# MCXA156 register map
Vendor: nxp.com; File version: 1.0
CPU: CM33 r2p0, little endian, no MPU, FPU, VTOR, 3 interrupt priority bits
Registers are 32-bit, read-write, reset 0x0 unless marked. A register's access mark holds for its fields unless they carry their own. Offsets are from the block's base; [hi:lo] are bit positions; lines under a group give offsets from that group; {n}, {i} and the like mark numbered series; 'fields as' and 'values as' point back to an identical list.

## I3C0 — I3C
Base 0x40002000
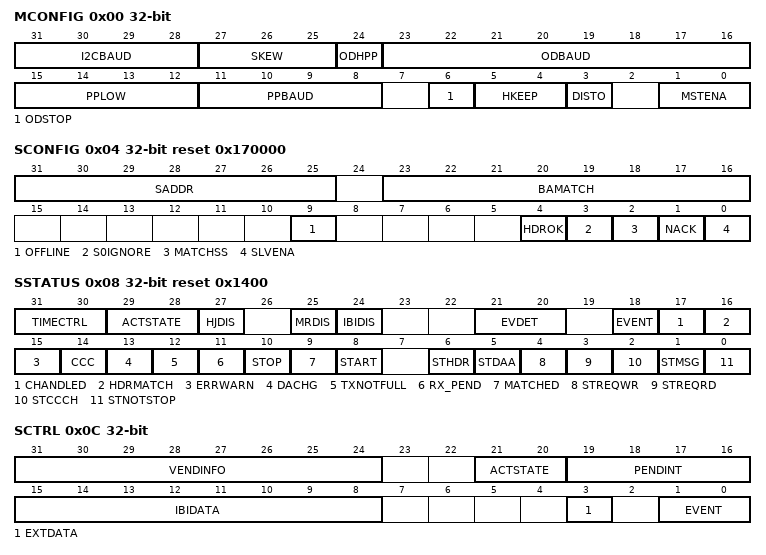
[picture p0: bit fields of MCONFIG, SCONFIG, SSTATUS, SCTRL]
0x00 MCONFIG — Controller Configuration
  [31:28] I2CBAUD — I2C Baud Rate
  [27:25] SKEW
  [24] ODHPP — Open Drain High Push-Pull
    0=DISABLE; 1=ENABLE
  [23:16] ODBAUD — Open Drain Baud Rate
  [15:12] PPLOW — Push-Pull Low
  [11:8] PPBAUD — Push-Pull Baud Rate
  [6] ODSTOP — Open Drain Stop
    0=DISABLE; 1=ENABLE
  [5:4] HKEEP — High-Keeper
    0=NONE; 1=WIRED_IN; 2=PASSIVE_SDA; 3=PASSIVE_ON_SDA_SCL
  [3] DISTO — Disable Timeout
    0=ENABLE (Enabled); 1=DISABLE (Disabled, if configured)
  [1:0] MSTENA — Controller Enable
    0=MASTER_OFF (CONTROLLER_OFF); 1=MASTER_ON (CONTROLLER_ON); 2=MASTER_CAPABLE (CONTROLLER_CAPABLE); 3=I2C_MASTER_MODE (I2C_CONTROLLER_MODE)
0x04 SCONFIG reset 0x170000 — Target Configuration
  [31:25] SADDR — Static Address
  [23:16] BAMATCH — Bus Available Match
  [9] OFFLINE
    0=DISABLE; 1=ENABLE
  [4] HDROK
    0=DISABLE (Disable HDR OK); 1=ENABLE (Enable HDR OK)
  [3] S0IGNORE — Ignore TE0 or TE1 Errors
    0=DISABLE (Do not ignore TE0 or TE1 errors); 1=ENABLE (Ignore TE0 or TE1 errors)
  [2] MATCHSS — Match Start or Stop
    0=DISABLE; 1=ENABLE
  [1] NACK — Not Acknowledge
    0=DISABLE (Always disable NACK mode); 1=ENABLE (Always enable NACK mode (works normally))
  [0] SLVENA — Target Enable
    0=DISABLE; 1=ENABLE
0x08 SSTATUS reset 0x1400 — Target Status
  [31:30] TIMECTRL ro — Time Control
    0=NO_TIME_CONTROL (NO_TIME_CONTROL (no time control is enabled)); 1=SYNC (SYNC_MODE (Synchronous mode is enabled)); 2=ASYNC_MODE (ASYNC_MODE (Asynchronous standard mode (0 or 1) is enabled)); 3=BOTHSYNCASYNC (BOTHSYNCASYNC (both Synchronous and Asynchronous modes are enabled))
  [29:28] ACTSTATE ro — Activity State from Common Command Codes (CCC)
    0=NO_LATENCY (NO_LATENCY (normal bus operations)); 1=LATENCY_1MS (LATENCY_1MS (1 ms of latency)); 2=LATENCY_100MS (LATENCY_100MS (100 ms of latency)); 3=LATENCY_10S (LATENCY_10S (10 seconds of latency))
  [27] HJDIS ro — Hot-Join Disabled
    0=MR_ENABLED (Enabled); 1=MR_DISABLED (Disabled)
  [25] MRDIS ro — Controller Requests Disable
    0=MR_ENABLED (Enabled); 1=MR_DISABLED (Disabled)
  [24] IBIDIS ro — In-Band Interrupts Disable
    0=INTERRUPTS_ENABLED (Enabled); 1=INTERRUPTS_DISABLED (Disabled)
  [21:20] EVDET ro — Event Details
    0=NONE (NONE (no event or no pending event)); 1=NO_REQUEST (NO_REQUEST (request is not sent yet; either there is no START condition yet, or is waiting for Bus-Available or Bus-Idle (HJ))); 2=NACKED (NACKed (not acknowledged, request sent and rejected); I3C tries again); 3=ACKED (ACKed (acknowledged; request sent and accepted), so done (unless the time control data is still being sent))
  [18] EVENT write-1-clears
    on read: 0=NO_EVENT (No event occurred); 1=EVENT (IBI, CR, or HJ occurred)
  [17] CHANDLED write-1-clears — Common Command Code Handled
    on read: 0=NOT_HANDLED (CCC handling not in progress); 1=HANDLED (CCC handling in progress)
  [16] HDRMATCH write-1-clears — High Data Rate Command Match
    on read: 0=NO_MATCH (Did not match); 1=MATCH (Matched the I3C dynamic address)
  [15] ERRWARN ro — Error Warning
  [14] CCC write-1-clears — Common Command Code
    on read: 0=NO_CCC_RECEIVED (CCC not received); 1=CCC_RECEIVED
  [13] DACHG write-1-clears — Dynamic Address Change
    on read: 0=NO_CHANGE_DETECTED (No DA change detected); 1=CHANGE_DETECTED (DA change detected)
  [12] TXNOTFULL ro — Transmit Buffer Not Full
    0=FULL (Transmit buffer full); 1=NOT_FULL (Transmit buffer not full)
  [11] RX_PEND ro — Received Message Pending
    0=NO_MSG_PENDING (No received message pending); 1=MSG_PENDING (Received message pending)
  [10] STOP write-1-clears
    on read: 0=NO_STOP_DETECTED (No Stopped state detected); 1=STOP_DETECTED (Stopped state detected)
  [9] MATCHED write-1-clears
    on read: 0=NOT_MATCHED (Header not matched); 1=MATCHED (Header matched)
  [8] START write-1-clears
    on read: 0=START_NOT_DETECTED (Not detected); 1=START_DETECTED (Detected)
  [6] STHDR ro — Status High Data Rate
    0=NOT_IN_HDR_DDR (I3C bus not in HDR-DDR mode); 1=IN_HDR_DDR (I3C bus in HDR-DDR mode)
  [5] STDAA ro — Status Dynamic Address Assignment
    0=NOT_IN_ENTDAA (Not in ENTDAA mode); 1=IN_ENTDAA (In ENTDAA mode)
  [4] STREQWR ro — Status Request Write
    0=IDLE (Not an SDR write); 1=BUSY (SDR write data from the controller, but not in ENTDAA mode)
  [3] STREQRD ro — Status Request Read
    0=IDLE (Not an SDR read); 1=BUSY (SDR read from this target or an IBI is being pushed out)
  [2] STCCCH ro — Status Common Command Code Handler
    0=IDLE (No CCC message handled); 1=BUSY (Handled automatically)
  [1] STMSG ro — Status Message
    0=IDLE; 1=BUSY
  [0] STNOTSTOP ro — Status not Stop
    0=STOPPED (In STOP condition); 1=BUSY
0x0C SCTRL — Target Control
  [31:24] VENDINFO — Vendor Information
  [21:20] ACTSTATE — Activity State of Target
  [19:16] PENDINT — Pending Interrupt
  [15:8] IBIDATA — In-Band Interrupt Data
  [3] EXTDATA — Extended Data
    0=DISABLE; 1=ENABLE
  [1:0] EVENT
    0=NORMAL_MODE; 1=IBI; 2=MASTER_REQUEST (CONTROLLER_REQUEST); 3=HOT_JOIN_REQUEST
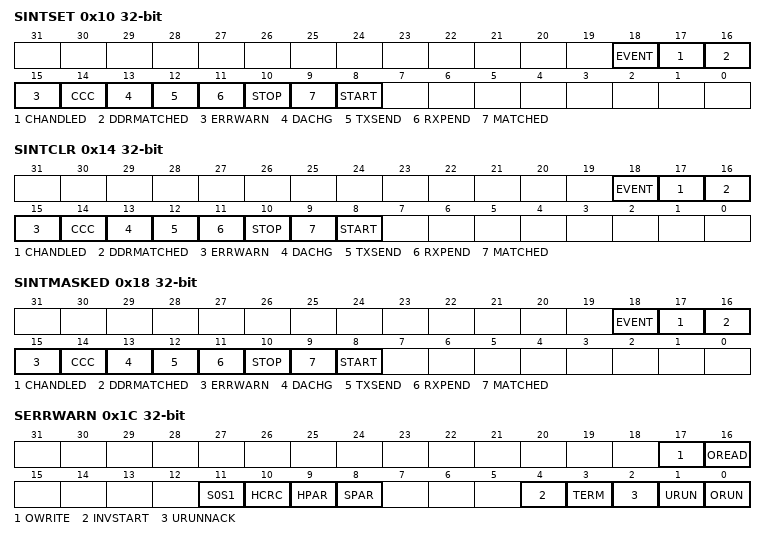
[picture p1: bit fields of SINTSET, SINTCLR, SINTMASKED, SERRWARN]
0x10 SINTSET write-1-sets — Target Interrupt Set
  [all] fields
    0=DISABLE; 1=ENABLE
  [18] EVENT write-1-sets — Event Interrupt Enable
  [17] CHANDLED write-1-sets — Common Command Code (CCC) Interrupt Enable
  [16] DDRMATCHED write-1-sets — Double Data Rate Interrupt Enable
  [15] ERRWARN write-1-sets — Error or Warning Interrupt Enable
  [14] CCC write-1-sets — Common Command Code (CCC) Interrupt Enable
  [13] DACHG write-1-sets — Dynamic Address Change Interrupt Enable
  [12] TXSEND write-1-sets — Transmit Interrupt Enable
  [11] RXPEND write-1-sets — Receive Interrupt Enable
  [10] STOP write-1-sets — Stop Interrupt Enable
  [9] MATCHED write-1-sets — Match Interrupt Enable
  [8] START write-1-sets — Start Interrupt Enable
0x14 SINTCLR reset not defined write-1-clears — Target Interrupt Clear
  [18] EVENT write-1-clears — EVENT Interrupt Enable Clear
  [17] CHANDLED write-1-clears — CHANDLED Interrupt Enable Clear
  [16] DDRMATCHED write-1-clears — DDRMATCHED Interrupt Enable Clear
  [15] ERRWARN write-1-clears — ERRWARN Interrupt Enable Clear
  [14] CCC write-1-clears — CCC Interrupt Enable Clear
  [13] DACHG write-1-clears — DACHG Interrupt Enable Clear
  [12] TXSEND write-1-clears — TXSEND Interrupt Enable Clear
  [11] RXPEND write-1-clears — RXPEND Interrupt Enable Clear
  [10] STOP write-1-clears — STOP Interrupt Enable Clear
  [9] MATCHED write-1-clears — Matched Interrupt Enable Clear
  [8] START write-1-clears — START Interrupt Enable Clear
0x18 SINTMASKED ro — Target Interrupt Mask
  [18] EVENT — EVENT Interrupt Mask
  [17] CHANDLED — CHANDLED Interrupt Mask
  [16] DDRMATCHED — DDRMATCHED Interrupt Mask
  [15] ERRWARN — ERRWARN Interrupt Mask
  [14] CCC — CCC Interrupt Mask
  [13] DACHG — DACHG Interrupt Mask
  [12] TXSEND — TXSEND Interrupt Mask
  [11] RXPEND — RXPEND Interrupt Mask
  [10] STOP — STOP Interrupt Mask
  [9] MATCHED — MATCHED Interrupt Mask
  [8] START — START Interrupt Mask
0x1C SERRWARN write-1-clears — Target Errors and Warnings
  [17] OWRITE write-1-clears — Over-Write Error
    on read: 0=NO_ERROR (No overwrite error); 1=ERROR (Overwrite error)
  [16] OREAD write-1-clears — Over-Read Error
    on read: 0=NO_ERROR (No over-read error); 1=ERROR (Over-read error)
  [11] S0S1 write-1-clears — TE0 or TE1 Error
    on read: 0=NO_ERROR (No TE0 or TE1 error occurred); 1=ERROR (TE0 or TE1 error occurred)
  [10] HCRC write-1-clears — HDR-DDR CRC Error
    on read: 0=NO_ERROR (No HDR-DDR CRC error occurred); 1=ERROR (HDR-DDR CRC error occurred)
  [9] HPAR write-1-clears — HDR Parity Error
    on read: 0=NO_ERROR (No HDR parity error); 1=ERROR (HDR parity error)
  [8] SPAR write-1-clears — SDR Parity Error
    on read: 0=NO_ERROR (No SDR parity error); 1=ERROR (SDR parity error)
  [4] INVSTART write-1-clears — Invalid Start Error
    on read: 0=NO_ERROR (No invalid start error); 1=ERROR (Invalid start error)
  [3] TERM write-1-clears — Terminated Error
    on read: 0=NO_ERROR (No terminated error); 1=ERROR (Terminated error)
  [2] URUNNACK write-1-clears — Underrun and Not Acknowledged (NACKed) Error
    on read: 0=NO_ERROR (No underrun; not acknowledged error); 1=ERROR (Underrun; not acknowledged error)
  [1] URUN write-1-clears — Underrun Error
    on read: 0=NO_ERROR (No underrun error); 1=ERROR (Underrun error)
  [0] ORUN write-1-clears — Overrun Error
    on read: 0=NO_ERROR (No overrun error); 1=ERROR (Overrun error)
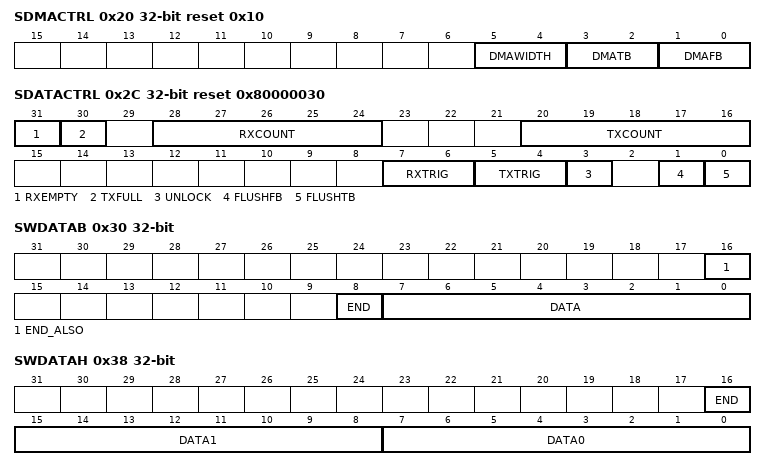
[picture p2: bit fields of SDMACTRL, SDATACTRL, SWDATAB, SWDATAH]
0x20 SDMACTRL reset 0x10 — Target DMA Control
  [5:4] DMAWIDTH — Width of DMA Operations
    0=BYTE_0; 1=BYTE_1; 2=HALF_WORD (Halfword (16 bits) (this value ensures that two bytes are available in the FIFO))
  [3:2] DMATB — DMA Write (To-Bus) Trigger
    0=NOT_USED (DMA not used); 1=ENABLE_ONE_FRAME (DMA enabled for one frame); 2=ENABLE (DMA enabled until turned off)
  [1:0] DMAFB — DMA Read (From-Bus) Trigger
    values as DMATB
0x2C SDATACTRL reset 0x80000030 — Target Data Control
  [31] RXEMPTY ro — Receive is Empty
    0=RXISNOTEMPTY (Not empty); 1=RXISEMPTY (Empty)
  [30] TXFULL ro — Transmit is Full
    0=TXISNOTFULL (Not full); 1=TXISFULL (Full)
  [28:24] RXCOUNT ro — Count of Bytes in Receive
  [20:16] TXCOUNT ro — Count of Bytes in Transmit
  [7:6] RXTRIG — Receive Trigger Level
    0=TRIGGRNOTEMPTY (Trigger when not empty); 1=TRIGGRONEFOURTH (Trigger when 1/4 or more full); 2=TRIGGRONEHALF (Trigger when 1/2 or more full); 3=TRIGGRTHREEFOURTHS (Trigger when 3/4 or more full)
  [5:4] TXTRIG — Transmit Trigger Level
    0=TRIGGREMPTY (Trigger when empty); 1=TRIGGRONEFOURTH (Trigger when 1/4 full or less); 2=TRIGGRONEHALF (Trigger when 1/2 full or less); 3=TRIGGRONELESS (Default (trigger when 1 less than full or less))
  [3] UNLOCK wo
    0=DISABLED (Cannot be changed); 1=ENABLED (Can be changed)
  [1] FLUSHFB wo — Flush From-Bus Buffer or FIFO
  [0] FLUSHTB wo — Flush To-Bus Buffer or FIFO
0x30 SWDATAB wo reset not defined — Target Write Data Byte
  [16] END_ALSO
    0=NOT_END (Not the end); 1=END
  [8] END
    0=NOT_END (Not the end); 1=END
  [7:0] DATA
0x34 SWDATABE wo reset not defined — Target Write Data Byte End
  [7:0] DATA
0x38 SWDATAH wo reset not defined — Target Write Data Halfword
  [16] END — End of Message
    0=NOT_END (Not the end); 1=END
  [15:8] DATA1
  [7:0] DATA0
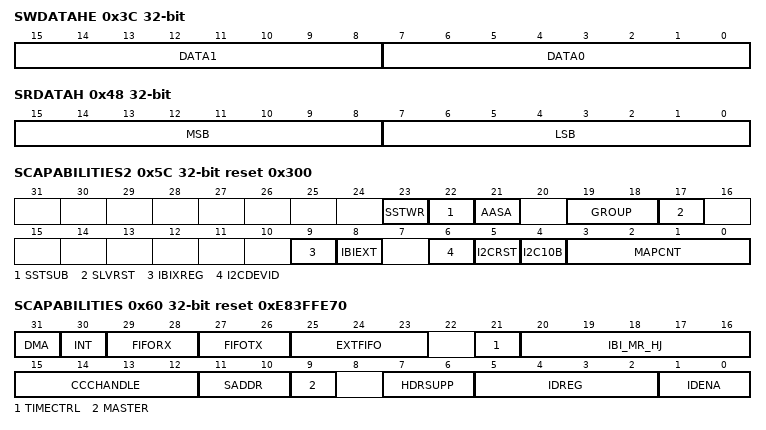
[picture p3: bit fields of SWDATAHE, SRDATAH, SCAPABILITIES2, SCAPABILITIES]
0x3C SWDATAHE wo reset not defined — Target Write Data Halfword End
  [15:8] DATA1, [7:0] DATA0
0x40 SRDATAB ro — Target Read Data Byte
  [7:0] DATA0
0x48 SRDATAH ro — Target Read Data Halfword
  [15:8] MSB — High Byte
  [7:0] LSB — Low Byte
0x54 SWDATAB1 wo (SWDATA_B_H view) — Target Write Data Byte
  [7:0] DATA
0x54 SWDATAH1 wo (SWDATA_B_H view) — Target Write Data Halfword
  [15:0] DATA
0x5C SCAPABILITIES2 ro reset 0x300 — Target Capabilities 2
  [23] SSTWR — Target-Target(s)-Tunnel Write Capable
    0=NOTSUPPORTED (Not write capable); 1=SUPPORTED (Write capable)
  [22] SSTSUB — Target-Target(s)-Tunnel Subscriber Capable
    0=NOTSUPPORTED (Not subscriber capable); 1=SUPPORTED (Subscriber capable)
  [21] AASA — SETAASA
    0=NOTSUPPORTED (SETAASA not supported); 1=SUPPORTED (SETAASA supported)
  [19:18] GROUP
    0=NOTSUPPORTED (v1.1 group addressing not supported); 1=ONE (One group supported); 2=TWO (Two groups supported); 3=THREE (Three groups supported)
  [17] SLVRST — Target Reset
    0=DISABLE (Not supported); 1=ENABLE (Supported)
  [9] IBIXREG — In-Band Interrupt Extended Register
    0=DISABLE (Not supported); 1=ENABLE (Supported)
  [8] IBIEXT — In-Band Interrupt EXTDATA
    0=DISABLE (Not supported); 1=ENABLE (Supported)
  [6] I2CDEVID — I2C Device ID
    0=DISABLE (Not supported); 1=ENABLE (Supported)
  [5] I2CRST — I2C Software Reset
    0=DISABLE (Not supported); 1=ENABLE (Supported)
  [4] I2C10B — I2C 10-bit Address
    0=DISABLE (Not supported); 1=ENABLE (Supported)
  [3:0] MAPCNT — Map Count
0x60 SCAPABILITIES ro reset 0xE83FFE70 — Target Capabilities
  [31] DMA — Direct Memory Access
    0=DMANO (Not supported); 1=DMAYES (Supported)
  [30] INT — Interrupts
    0=INTERRUPTSNO (Not supported); 1=INTERRUPTSYES (Supported)
  [29:28] FIFORX — FIFO Receive
    0=FIFO_2BYTE (Two or three); 1=FIFO_4BYTE (Four); 2=FIFO_8BYTE (Eight); 3=FIFO_16BYTE (16 or larger)
  [27:26] FIFOTX — FIFO Transmit
    0=FIFO_2BYTE (Two); 1=FIFO_4BYTE (Four); 2=FIFO_8BYTE (Eight); 3=FIFO_16BYTE (16 or larger)
  [25:23] EXTFIFO — External FIFO
    0=NO_EXT_FIFO (No external FIFO available); 1=STD_EXT_FIFO (Standard available or free external FIFO); 2=REQUEST_EXT_FIFO (Request track external FIFO)
  [21] TIMECTRL — Time Control
    0=NO_TIME_CONTROL_TYPE (No time control supported); 1=ATLEAST1_TIME_CONTROL (At least one time-control type supported)
  [20:16] IBI_MR_HJ — In-Band Interrupts, Controller Requests, Hot-Join Events
    0=ALL_DISABLED (Application cannot generate IBI, CR, or HJ); 0bxxxx1=IBI (Application can generate an IBI)
  [15:12] CCCHANDLE — Common Command Codes Handling
    0=ALL_DISABLED (All handling features disabled); 0bxxx1=BLOCK_HANDLE (The I3C module manages events, activities, status, HDR, and if enabled for it, ID and static-address-related items)
  [11:10] SADDR — Static Address
    0=NO_STATIC (No static address); 1=STATIC (Static address is fixed in hardware); 2=HW_CONTROL (Hardware controls the static address dynamically (for example, from the pin strap)); 3=CONFIG (SCONFIG register supplies the static address)
  [9] MASTER — Controller
    0=MASTERNOTSUPPORTED (Not supported); 1=MASTERSUPPORTED (Supported)
  [7:6] HDRSUPP — High Data Rate Support
    0=NO_HDR (No HDR modes supported); 1=DDR (DDR mode supported)
  [5:2] IDREG — ID Register
    0=ALL_DISABLED (All ID register features disabled); 0bxxx1=ID_INSTANCE (ID Instance is a register; used if there is no PARTNO register)
  [1:0] IDENA — ID 48b Handler
    0=APPLICATION; 1=HW (Hardware); 2=HW_BUT (Hardware, but the I3C module instance handles ID 48b); 3=PARTNO (A part number register (PARTNO))
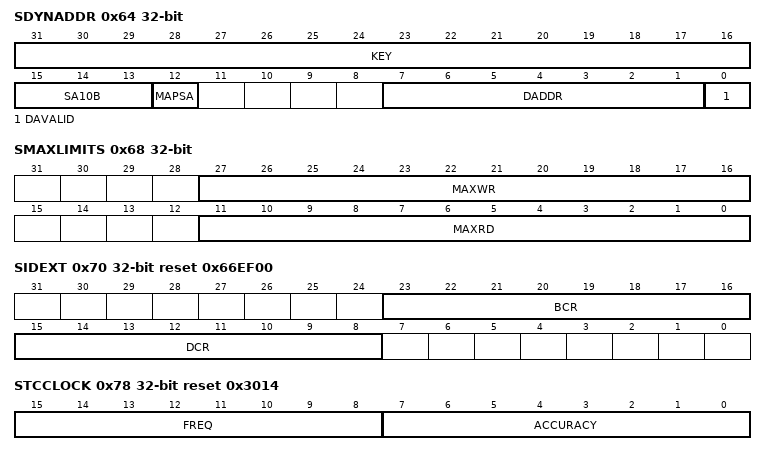
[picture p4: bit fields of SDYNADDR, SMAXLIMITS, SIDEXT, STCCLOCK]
0x64 SDYNADDR — Target Dynamic Address
  [31:16] KEY
  [15:13] SA10B wo — 10-Bit Static Address
  [12] MAPSA wo — Map a Static Address
  [7:1] DADDR — Dynamic Address
  [0] DAVALID — Dynamic Address Valid
    0=DANOTASSIGNED (DANOTASSIGNED: a dynamic address is not assigned); 1=DAASSIGNED (DAASSIGNED: a dynamic address is assigned)
0x68 SMAXLIMITS — Target Maximum Limits
  [27:16] MAXWR — Maximum Write Length
  [11:0] MAXRD — Maximum Read Length
0x6C SIDPARTNO reset 0x30000000 — Target ID Part Number
  [31:0] PARTNO — Part Number
0x70 SIDEXT reset 0x66EF00 — Target ID Extension
  [23:16] BCR — Bus Characteristics Register
  [15:8] DCR — Device Characteristic Register
0x74 SVENDORID reset 0x11B — Target Vendor ID
  [14:0] VID — Vendor ID
0x78 STCCLOCK reset 0x3014 — Target Time Control Clock
  [15:8] FREQ — Clock Frequency
  [7:0] ACCURACY — Clock Accuracy
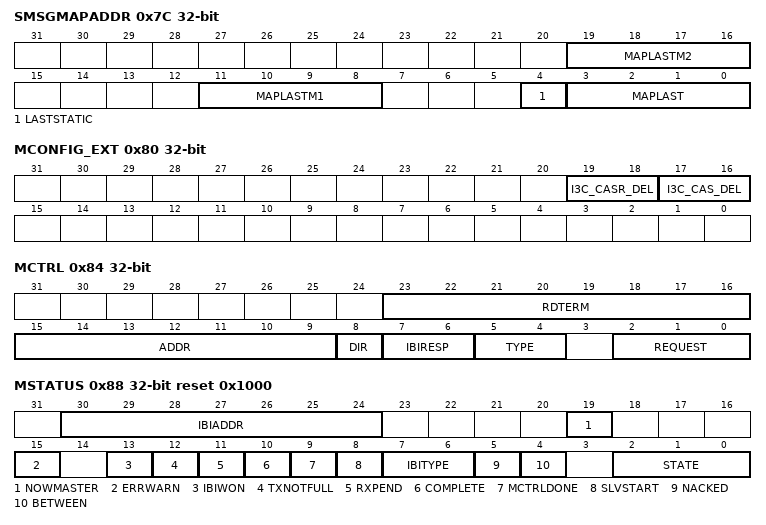
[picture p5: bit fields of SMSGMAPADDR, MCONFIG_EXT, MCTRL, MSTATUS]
0x7C SMSGMAPADDR ro — Target Message Map Address
  [19:16] MAPLASTM2 — Matched Previous Index 2
  [11:8] MAPLASTM1 — Matched Previous Address Index 1
  [4] LASTSTATIC — Last Static Address Matched
    0=I3C (I3C dynamic address); 1=I2C (I2C static address)
  [3:0] MAPLAST — Matched Address Index
0x80 MCONFIG_EXT — Controller Extended Configuration
  [19:18] I3C_CASR_DEL — I3C CAS Delay After Repeated START
    0=NO_DELAY; 1=ONE_HALF_CLK (Increases SCL clock period by 1/2); 2=ONE_CLK (Increases SCL clock period by 1); 3=ONE_AND_ONE_HALF_CLK (Increases SCL clock period by 1 1/2)
  [17:16] I3C_CAS_DEL — I3C CAS Delay After START
    0=NO_DELAY; 1=ONE_HALF_CLK (Increases SCL clock period by 1/2); 2=ONE_CLK (Increases SCL clock period by 1); 3=ONE_AND_ONE_HALF_CLK (Increases SCL clock period by 3/2)
0x84 MCTRL — Controller Control
  [23:16] RDTERM — Read Terminate Counter
  [15:9] ADDR — Address
  [8] DIR — Direction
    0=DIRWRITE (Write); 1=DIRREAD (Read)
  [7:6] IBIRESP — In-Band Interrupt Response
    0=ACK (ACK (acknowledge)); 1=NACK (NACK (reject)); 2=ACK_WITH_MANDATORY (Acknowledge with mandatory byte); 3=MANUAL
  [5:4] TYPE — Bus Type with EmitStartAddr
    0=I3C; 1=I2C; 2=DDR
  [2:0] REQUEST
    0=NONE; 1=EMITSTARTADDR; 2=EMITSTOP; 3=IBIACKNACK; 4=PROCESSDAA; 6=FORCEEXIT (Force Exit and Target Reset); 7=AUTOIBI
0x88 MSTATUS reset 0x1000 — Controller Status
  [30:24] IBIADDR ro — IBI Address
  [19] NOWMASTER write-1-clears — Module is now Controller
    on read: 0=NOT_MASTER (Not a controller); 1=MASTER (Controller)
  [15] ERRWARN ro — Error or Warning
    0=NO_ERROR (No error or warning); 1=ERROR (Error or warning)
  [13] IBIWON write-1-clears — In-Band Interrupt (IBI) Won
    on read: 0=NOT_WON (No IBI arbitration won); 1=WON (IBI arbitration won)
  [12] TXNOTFULL ro — TX Buffer or FIFO Not Full
    0=FULL (Receive buffer or FIFO full); 1=NOTFULL (Receive buffer or FIFO not full)
  [11] RXPEND ro
    0=IDLE (No receive message pending); 1=PENDING (Receive message pending)
  [10] COMPLETE write-1-clears
    on read: 0=NOT_COMPLETE; 1=COMPLETE
  [9] MCTRLDONE write-1-clears — Controller Control Done
    on read: 0=NOT_DONE; 1=DONE
  [8] SLVSTART write-1-clears — Target Start
    on read: 0=NOT_START (Target not requesting START); 1=START (Target requesting START)
  [7:6] IBITYPE ro — In-Band Interrupt (IBI) Type
    0=NONE (NONE (no IBI: this status occurs when MSTATUS[IBIWON] becomes 0)); 1=IBI; 2=MR (CR); 3=HJ
  [5] NACKED ro — Not Acknowledged
    0=NOT_NACKED; 1=NACKED (NACKed (not acknowledged))
  [4] BETWEEN ro
    0=INACTIVE (Inactive (for other cases)); 1=ACTIVE
  [2:0] STATE ro — State of the Controller
    0=IDLE (IDLE (bus has stopped)); 1=SLVREQ (SLVREQ (target request)); 2=MSGSDR; 3=NORMACT; 4=DDR (MSGDDR); 5=DAA; 6=IBIACK; 7=IBIRCV
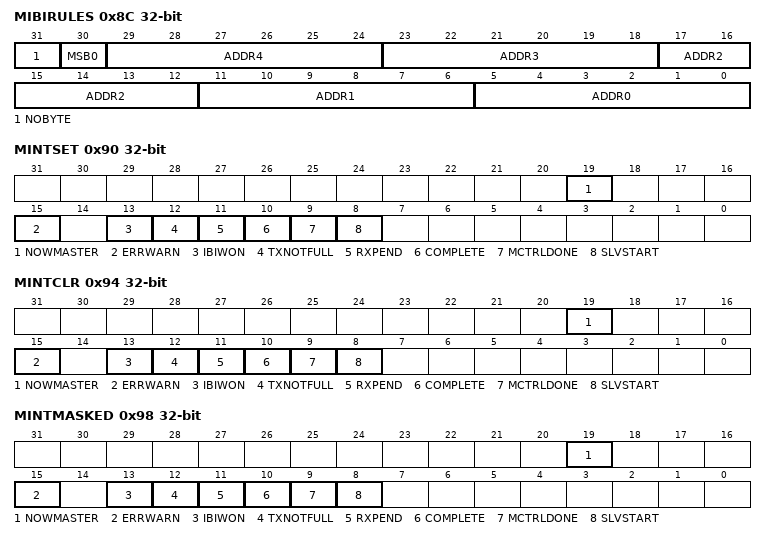
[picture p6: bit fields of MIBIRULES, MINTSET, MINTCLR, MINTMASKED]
0x8C MIBIRULES — Controller In-band Interrupt Registry and Rules
  [31] NOBYTE — No IBI byte
    0=IBIBYTE (With mandatory IBI byte); 1=NO_IBIBYTE (Without mandatory IBI byte)
  [30] MSB0 — Most Significant Address Bit is 0
    0=DISABLE (MSB is not 0); 1=ENABLE (MSB is 0)
  [6n+5:6n] ADDR{n} (n=0..4)
0x90 MINTSET write-1-sets — Controller Interrupt Set
  [19] NOWMASTER write-1-sets — Now Controller Interrupt Enable
    0=DISABLE; 1=ENABLE
  [15] ERRWARN write-1-sets — Error or Warning (ERRWARN) Interrupt Enable
    0=DISABLE; 1=ENABLE
  [13] IBIWON write-1-sets — IBI Won Interrupt Enable
    0=DISABLE; 1=ENABLE
  [12] TXNOTFULL write-1-sets — Transmit Buffer/FIFO Not Full Interrupt Enable
    0=DISABLE; 1=ENABLE
  [11] RXPEND write-1-sets — Receive Pending Interrupt Enable
  [10] COMPLETE write-1-sets — Completed Message Interrupt Enable
    0=DISABLE; 1=ENABLE
  [9] MCTRLDONE write-1-sets — Controller Control Done Interrupt Enable
    0=DISABLE; 1=ENABLE
  [8] SLVSTART write-1-sets — Target Start Interrupt Enable
    0=DISABLE; 1=ENABLE
0x94 MINTCLR reset not defined write-1-clears — Controller Interrupt Clear
  [all] fields
    on read: 0=NONE (No effect); 1=CLEAR (Interrupt enable cleared)
  [19] NOWMASTER write-1-clears — NOWCONTROLLER Interrupt Enable Clear
  [15] ERRWARN write-1-clears — ERRWARN Interrupt Enable Clear
  [13] IBIWON write-1-clears — IBIWON Interrupt Enable Clear
  [12] TXNOTFULL write-1-clears — TXNOTFULL Interrupt Enable Clear
  [11] RXPEND write-1-clears — RXPEND Interrupt Enable Clear
  [10] COMPLETE write-1-clears — COMPLETE Interrupt Enable Clear
  [9] MCTRLDONE write-1-clears — MCTRLDONE Interrupt Enable Clear
  [8] SLVSTART write-1-clears — SLVSTART Interrupt Enable Clear
0x98 MINTMASKED ro — Controller Interrupt Mask
  [19] NOWMASTER — NOWCONTROLLER Interrupt Mask
    0=NOT_ENABLED (Disabled); 1=ENABLED
  [15] ERRWARN — ERRWARN Interrupt Mask
    0=NOT_ENABLED (Disabled); 1=ENABLED
  [13] IBIWON — IBIWON Interrupt Mask
    0=NOT_ENABLED (Disabled); 1=ENABLED
  [12] TXNOTFULL — TXNOTFULL Interrupt Mask
    0=NOT_ENABLED (Disabled); 1=ENABLED
  [11] RXPEND — RXPEND Interrupt Mask
  [10] COMPLETE — COMPLETE Interrupt Mask
    0=NOT_ENABLED (Disabled); 1=ENABLED
  [9] MCTRLDONE — MCTRLDONE Interrupt Mask
    0=NOT_ENABLED (Disabled); 1=ENABLED
  [8] SLVSTART — SLVSTART Interrupt Mask
    0=NOT_ENABLED (Disabled); 1=ENABLED
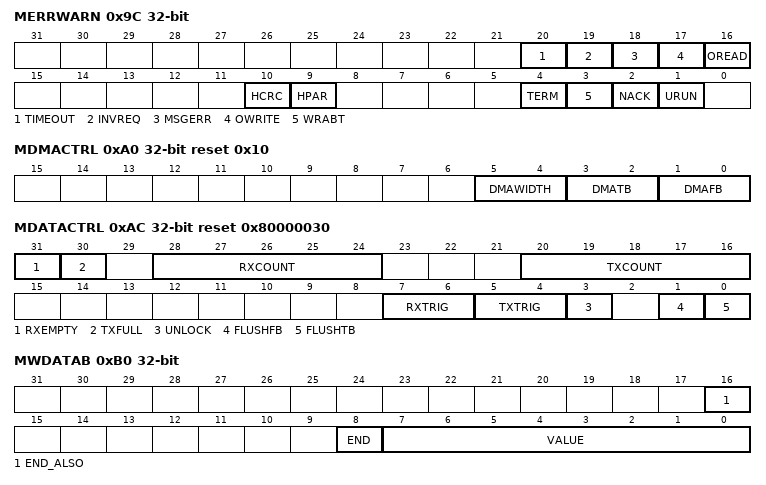
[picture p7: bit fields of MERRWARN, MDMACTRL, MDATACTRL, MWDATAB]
0x9C MERRWARN write-1-clears — Controller Errors and Warnings
  [all] fields
    on read: 0=NO_ERROR; 1=ERROR
  [20] TIMEOUT write-1-clears — Timeout Error
  [19] INVREQ write-1-clears — Invalid Request Error
  [18] MSGERR write-1-clears — Message Error
  [17] OWRITE write-1-clears — Overwrite Error
  [16] OREAD write-1-clears — Overread Error
  [10] HCRC write-1-clears — High Data Rate CRC Error
  [9] HPAR write-1-clears — High Data Rate Parity
  [4] TERM write-1-clears — Terminate Error
  [3] WRABT write-1-clears — Write Abort Error
  [2] NACK write-1-clears — Not Acknowledge Error
  [1] URUN write-1-clears — Underrun Error
0xA0 MDMACTRL reset 0x10 — Controller DMA Control
  [5:4] DMAWIDTH
    0=BYTE_0; 1=BYTE_1; 2=HALF_WORD (Halfword (16 bits))
  [3:2] DMATB — DMA to Bus
    0=NOT_USED (DMA not used); 1=ENABLE_ONE_FRAME (Enable DMA for one frame (ended by DMA or terminated)); 2=ENABLE (Enable DMA until DMA is turned off)
  [1:0] DMAFB — DMA from Bus
    0=NOT_USED (DMA not used); 1=ENABLE_ONE_FRAME (Enable DMA for one frame); 2=ENABLE (Enable DMA until DMA is turned off)
0xAC MDATACTRL reset 0x80000030 — Controller Data Control
  [31] RXEMPTY ro — Receive is Empty
    0=NOT_EMPTY; 1=EMPTY
  [30] TXFULL ro — Transmit is Full
    0=NOT_FULL; 1=FULL
  [28:24] RXCOUNT ro — Receive Byte Count
  [20:16] TXCOUNT ro — Transmit Byte Count
  [7:6] RXTRIG — Receive Trigger Level
    0=NOT_EMPTY (Trigger when not empty); 1=QUARTER_OR_MORE (Trigger when 1/4 full or more); 2=HALF_OR_MORE (Trigger when 1/2 full or more); 3=THREE_QUARTER_OR_MORE (Trigger when 3/4 full or more)
  [5:4] TXTRIG — Transmit Trigger Level
    0=EMPTY (Trigger when empty); 1=QUARTER_OR_LESS (Trigger when 1/4 full or less); 2=HALF_OR_LESS (Trigger when 1/2 full or less); 3=FULL_OR_LESS (Trigger when 1 less than full or less (default))
  [3] UNLOCK wo
    0=DISABLED (Locked); 1=ENABLED (Unlocked)
  [1] FLUSHFB wo — Flush From-Bus Buffer or FIFO
    0=NO_ACTION; 1=FLUSH (Flush the buffer)
  [0] FLUSHTB wo — Flush To-Bus Buffer or FIFO
    0=NO_ACTION; 1=FLUSH (Flush the buffer)
0xB0 MWDATAB wo reset not defined — Controller Write Data Byte
  [16] END_ALSO — End of Message ALSO
    0=NOT_END (Not the end); 1=END
  [8] END — End of Message
    0=NOT_END (Not the end); 1=END
  [7:0] VALUE — Data Byte
0xB4 MWDATABE wo reset not defined — Controller Write Data Byte End
  [7:0] VALUE — Data
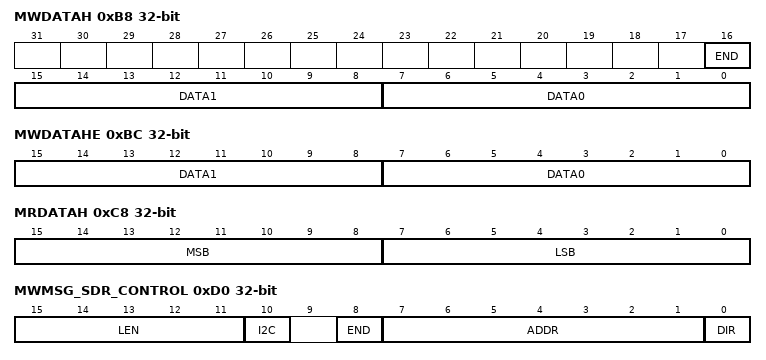
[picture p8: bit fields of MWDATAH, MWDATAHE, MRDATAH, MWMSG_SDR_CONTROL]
0xB8 MWDATAH wo reset not defined — Controller Write Data Halfword
  [16] END — End of Message
    0=NOT_END (Not the end); 1=END
  [15:8] DATA1 — Data Byte 1
  [7:0] DATA0 — Data Byte 0
0xBC MWDATAHE wo reset not defined — Controller Write Data Halfword End
  [15:8] DATA1 — Data Byte 1
  [7:0] DATA0 — Data Byte 0
0xC0 MRDATAB ro — Controller Read Data Byte
  [7:0] VALUE
0xC8 MRDATAH ro — Controller Read Data Halfword
  [15:8] MSB — High Byte
  [7:0] LSB — Low Byte
0xCC MWDATAB1 wo (MWDATA_B1_H1 view) — Controller Write Byte Data 1 (to Bus)
  [7:0] VALUE
0xCC MWDATAH1 wo (MWDATA_B1_H1 view) — Controller Write Halfword Data (to Bus)
  [15:0] VALUE
0xD0 MWMSG_SDR_CONTROL wo reset not defined (MWMSG_SDR view) — Controller Write Message Control in SDR mode
  [15:11] LEN — Length
  [10] I2C
    0=I3CMESSAGE; 1=I2CMESSAGE
  [8] END — End of SDR Message
    0=NOT_END (Not the end); 1=END
  [7:1] ADDR — Address
  [0] DIR — Direction
    0=WRITE; 1=READ
0xD0 MWMSG_SDR_DATA wo (MWMSG_SDR view) — Controller Write Message Data in SDR mode
  [15:0] DATA16B — Data
0xD4 MRMSG_SDR ro — Controller Read Message in SDR mode
  [15:0] DATA
0xD8 MWMSG_DDR_CONTROL wo reset not defined (MWMSG_DDR view) — Controller Write Message in DDR mode: First Control Word
  [15:0] ADDRCMD — Address Command
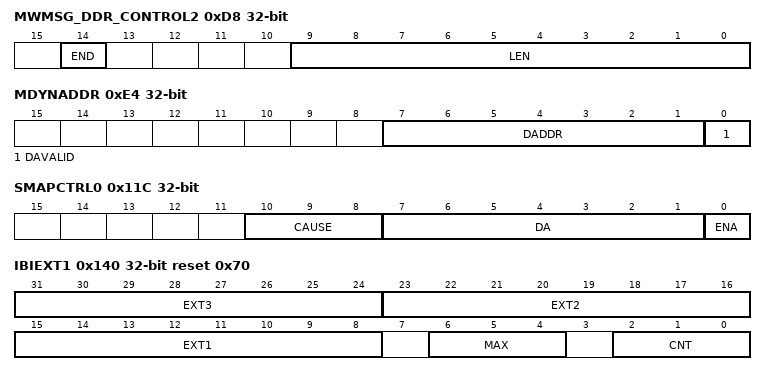
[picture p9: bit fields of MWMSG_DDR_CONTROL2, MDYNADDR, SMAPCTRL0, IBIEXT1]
0xD8 MWMSG_DDR_CONTROL2 wo reset not defined (MWMSG_DDR view) — Controller Write Message in DDR Mode Control 2
  [14] END — End of Message
    0=NOT_END (Not the end); 1=END
  [9:0] LEN — Length of Message
0xD8 MWMSG_DDR_DATA wo (MWMSG_DDR view) — Controller Write Message Data in DDR mode
  [15:0] DATA16B — Data
0xDC MRMSG_DDR ro — Controller Read Message in DDR mode
  [15:0] DATA
0xE4 MDYNADDR — Controller Dynamic Address
  [7:1] DADDR — Dynamic Address
  [0] DAVALID — Dynamic Address Valid
    0=NO_VALID (No valid DA assigned); 1=VALID (Valid DA assigned)
0x11C SMAPCTRL0 ro — Map Feature Control 0
  [10:8] CAUSE
    0=NONE (No information (this value occurs when not configured to write DA)); 1=ENTDAA (Set using ENTDAA); 2=SETDASA (Set using SETDASA, SETAASA, or SETNEWDA); 3=RSTDAA (Cleared using RSTDAA); 4=AUTOMAP (Auto MAP change happened last)
  [7:1] DA — Dynamic Address
  [0] ENA — Enable Primary Dynamic Address
    0=DISABLE (Disabled); 1=ENABLE (Enabled)
0x140 IBIEXT1 reset 0x70 — Extended IBI Data 1
  [31:24] EXT3 — Extra Byte 3
  [23:16] EXT2 — Extra Byte 2
  [15:8] EXT1 — Extra Byte 1
  [6:4] MAX ro — Maximum
  [2:0] CNT — Count
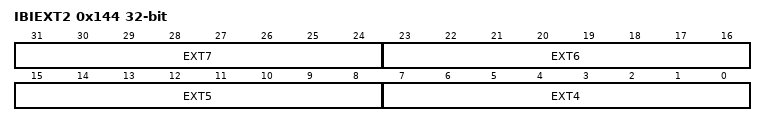
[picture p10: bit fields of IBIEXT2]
0x144 IBIEXT2 — Extended IBI Data 2
  [8n-25:8n-32] EXT{n} (n=4..7) — Extra Byte {n}
0xFFC SID ro reset 0xEDCB0100 — Target Module ID
  [31:0] ID
